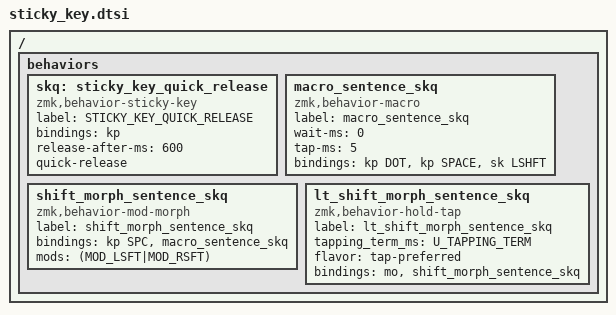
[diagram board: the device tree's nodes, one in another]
// Copyright 2022 Lukas Kucera
// https://github.com/kucera-lukas/zmk-config

#include <behaviors.dtsi>
#include <dt-bindings/zmk/keys.h>

/ {
    behaviors {
      skq: sticky_key_quick_release {
        compatible = "zmk,behavior-sticky-key";
        label = "STICKY_KEY_QUICK_RELEASE";
        #binding-cells = <1>;
        bindings = <&kp>;
        release-after-ms = <600>; // release after 0.6s
        quick-release;  // no double capitalization when rolling keys
      };

      macro_sentence_skq: macro_sentence_skq {
        compatible = "zmk,behavior-macro";
        label = "macro_sentence_skq";
        #binding-cells = <0>;
        wait-ms = <0>;
        tap-ms = <5>;
        bindings = <&kp DOT &kp SPACE &sk LSHFT>;
      };

      shift_morph_sentence_skq: shift_morph_sentence_skq {
        compatible = "zmk,behavior-mod-morph";
        label = "shift_morph_sentence_skq";
        #binding-cells = <0>;
        bindings = <&kp SPC>, <&macro_sentence_skq>;
        mods = <(MOD_LSFT|MOD_RSFT)>;
    };

    lt_shift_morph_sentence_skq: lt_shift_morph_sentence_skq {
      compatible = "zmk,behavior-hold-tap";
      label = "lt_shift_morph_sentence_skq";
      #binding-cells = <2>;
      tapping_term_ms = <U_TAPPING_TERM>;
      flavor = "tap-preferred";
      bindings = <&mo>, <&shift_morph_sentence_skq>;
    };
  };
};
